# ATSAMA5D31 register map
Vendor: Microchip Technology; Series: SAMA5D3; File version: 0
Registers are 32-bit, read-write, reset 0x0 unless marked. A register's access mark holds for its fields unless they carry their own. Offsets are from the block's base; [hi:lo] are bit positions; 'fields as' and 'values as' point back to an identical list.

## DBGU — Debug Unit
Base 0xFFFFEE00
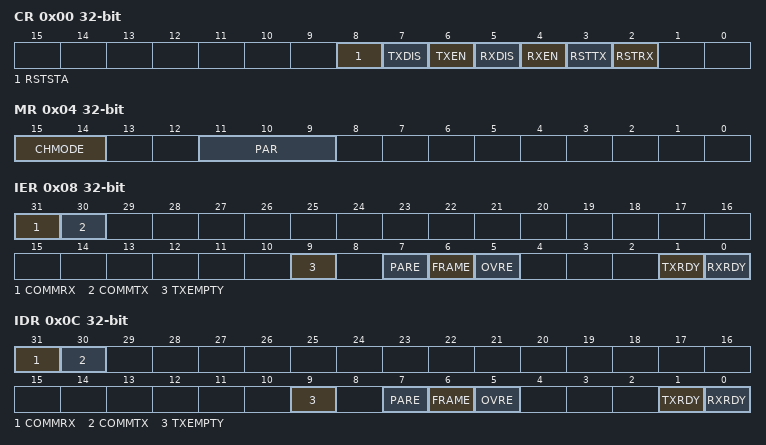
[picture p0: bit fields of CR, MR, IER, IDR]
0x00 CR wo — Control Register
  [8] RSTSTA — Reset Status Bits
  [7] TXDIS — Transmitter Disable
  [6] TXEN — Transmitter Enable
  [5] RXDIS — Receiver Disable
  [4] RXEN — Receiver Enable
  [3] RSTTX — Reset Transmitter
  [2] RSTRX — Reset Receiver
0x04 MR — Mode Register
  [15:14] CHMODE — Channel Mode
    0=NORM (Normal Mode); 1=AUTO (Automatic Echo); 2=LOCLOOP (Local Loopback); 3=REMLOOP (Remote Loopback)
  [11:9] PAR — Parity Type
    0=EVEN (Even Parity); 1=ODD (Odd Parity); 2=SPACE (Space: Parity forced to 0); 3=MARK (Mark: Parity forced to 1); 4=NONE (No Parity)
0x08 IER wo — Interrupt Enable Register
  [31] COMMRX — Enable COMMRX (from ARM) Interrupt
  [30] COMMTX — Enable COMMTX (from ARM) Interrupt
  [9] TXEMPTY — Enable TXEMPTY Interrupt
  [7] PARE — Enable Parity Error Interrupt
  [6] FRAME — Enable Framing Error Interrupt
  [5] OVRE — Enable Overrun Error Interrupt
  [1] TXRDY — Enable TXRDY Interrupt
  [0] RXRDY — Enable RXRDY Interrupt
0x0C IDR wo — Interrupt Disable Register
  [31] COMMRX — Disable COMMRX (from ARM) Interrupt
  [30] COMMTX — Disable COMMTX (from ARM) Interrupt
  [9] TXEMPTY — Disable TXEMPTY Interrupt
  [7] PARE — Disable Parity Error Interrupt
  [6] FRAME — Disable Framing Error Interrupt
  [5] OVRE — Disable Overrun Error Interrupt
  [1] TXRDY — Disable TXRDY Interrupt
  [0] RXRDY — Disable RXRDY Interrupt
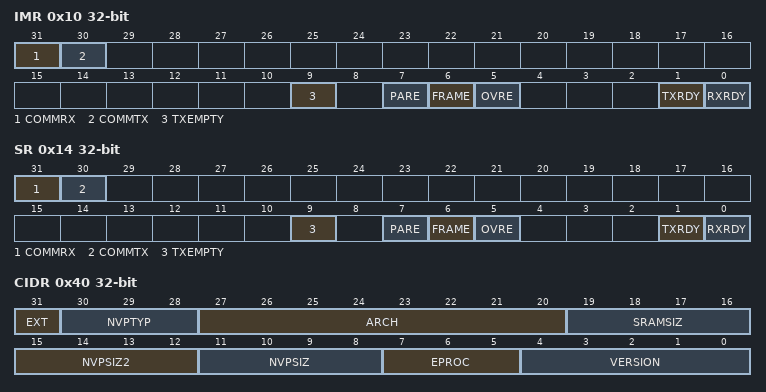
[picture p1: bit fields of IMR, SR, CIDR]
0x10 IMR ro — Interrupt Mask Register
  [31] COMMRX — Mask COMMRX Interrupt
  [30] COMMTX — Mask COMMTX Interrupt
  [9] TXEMPTY — Mask TXEMPTY Interrupt
  [7] PARE — Mask Parity Error Interrupt
  [6] FRAME — Mask Framing Error Interrupt
  [5] OVRE — Mask Overrun Error Interrupt
  [1] TXRDY — Disable TXRDY Interrupt
  [0] RXRDY — Mask RXRDY Interrupt
0x14 SR ro — Status Register
  [31] COMMRX — Debug Communication Channel Read Status
  [30] COMMTX — Debug Communication Channel Write Status
  [9] TXEMPTY — Transmitter Empty
  [7] PARE — Parity Error
  [6] FRAME — Framing Error
  [5] OVRE — Overrun Error
  [1] TXRDY — Transmitter Ready
  [0] RXRDY — Receiver Ready
0x18 RHR ro — Receive Holding Register
  [7:0] RXCHR — Received Character
0x1C THR wo — Transmit Holding Register
  [7:0] TXCHR — Character to be Transmitted
0x20 BRGR — Baud Rate Generator Register
  [15:0] CD — Clock Divisor
    0=DISABLED (DBGU Disabled); 1=MCK (Peripheral clock)
0x40 CIDR ro — Chip ID Register
  [31] EXT — Extension Flag
  [30:28] NVPTYP — Nonvolatile Program Memory Type
    0=ROM; 1=ROMLESS (ROMless or on-chip Flash); 2=FLASH (Embedded Flash Memory); 3=ROM_FLASH (ROM and Embedded Flash MemoryNVPSIZ is ROM size NVPSIZ2 is Flash size); 4=SRAM (SRAM emulating ROM)
  [27:20] ARCH — Architecture Identifier
    25=AT91SAM9xx Series; 41=AT91SAM9XExx Series; 52=AT91x34 Series; 55=CAP7 (CAP7 Series); 57=CAP9 (CAP9 Series); 59=CAP11 (CAP11 Series); 64=AT91x40 Series; 66=AT91x42 Series; 85=AT91x55 Series; 96=AT91SAM7Axx Series; 97=AT91SAM7AQxx Series; 99=AT91x63 Series; 112=AT91SAM7Sxx Series; 113=AT91SAM7XCxx Series; 114=AT91SAM7SExx Series; 115=AT91SAM7Lxx Series; 117=AT91SAM7Xxx Series; 118=AT91SAM7SLxx Series; 128=ATSAM3UxC Series (100-pin version); 129=ATSAM3UxE Series (144-pin version); 131=ATSAM3AxC Series (100-pin version); 132=ATSAM3XxC Series (100-pin version); 133=ATSAM3XxE Series (144-pin version); 134=ATSAM3XxG Series (208/217-pin version); 136=ATSAM3SxA Series (48-pin version); 137=ATSAM3SxB Series (64-pin version); 138=ATSAM3SxC Series (100-pin version); 146=AT91x92 Series; 147=ATSAM3NxA Series (48-pin version); 148=ATSAM3NxB Series (64-pin version); 149=ATSAM3NxC Series (100-pin version); 152=ATSAM3SDxA Series (48-pin version); 153=ATSAM3SDxB Series (64-pin version); 154=ATSAM3SDxC Series (100-pin version); 165=ATSAMA5xx Series; 240=AT75Cxx Series
  [19:16] SRAMSIZ — Internal SRAM Size
    1=_1K (1 Kbytes); 2=_2K (2 Kbytes); 3=_6K (6 Kbytes); 4=_112K (112 Kbytes); 5=_4K (4 Kbytes); 6=_80K (80 Kbytes); 7=_160K (160 Kbytes); 8=_8K (8 Kbytes); 9=_16K (16 Kbytes); 10=_32K (32 Kbytes); 11=_64K (64 Kbytes); 12=_128K (128 Kbytes); 13=_256K (256 Kbytes); 14=_96K (96 Kbytes); 15=_512K (512 Kbytes)
  [15:12] NVPSIZ2 — Second Nonvolatile Program Memory Size
    0=NONE; 1=_8K (8 Kbytes); 2=_16K (16 Kbytes); 3=_32K (32 Kbytes); 5=_64K (64 Kbytes); 7=_128K (128 Kbytes); 9=_256K (256 Kbytes); 10=_512K (512 Kbytes); 12=_1024K (1024 Kbytes); 14=_2048K (2048 Kbytes)
  [11:8] NVPSIZ — Nonvolatile Program Memory Size
    values as NVPSIZ2
  [7:5] EPROC — Embedded Processor
    1=ARM946ES; 2=ARM7TDMI; 3=CM3 (Cortex-M3); 4=ARM920T; 5=ARM926EJS; 6=CA5 (Cortex-A5)
  [4:0] VERSION — Version of the Device
0x44 EXID ro — Chip ID Extension Register
  [31:0] EXID — Chip ID Extension
0x48 FNR — Force NTRST Register
  [0] FNTRST — Force NTRST

## Notices in the file
Copyright (c) 2026 Microchip Technology Inc.
SPDX-License-Identifier: Apache-2.0
Licensed under the Apache License, Version 2.0 (the "License");
you may not use this file except in compliance with the License.
You may obtain a copy of the License at
http://www.apache.org/licenses/LICENSE-2.0
Unless required by applicable law or agreed to in writing, software
distributed under the License is distributed on an "AS IS" BASIS,
WITHOUT WARRANTIES OR CONDITIONS OF ANY KIND, either express or implied.
See the License for the specific language governing permissions and
limitations under the License.
